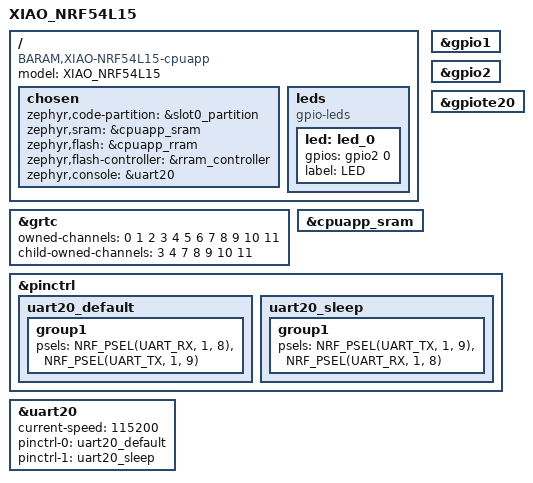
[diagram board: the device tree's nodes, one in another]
/dts-v1/;
#include <nordic/nrf54l15_cpuapp.dtsi>
#include "XIAO_NRF54L15-pinctrl.dtsi"

/ {
	model = "XIAO_NRF54L15";
	compatible = "BARAM,XIAO-NRF54L15-cpuapp";

	chosen {
		zephyr,code-partition = &slot0_partition;
		zephyr,sram = &cpuapp_sram;
		zephyr,flash = &cpuapp_rram;
		zephyr,flash-controller = &rram_controller;
    zephyr,console = &uart20;
	};

  leds {
    compatible = "gpio-leds";
    led: led_0 {
      gpios = <&gpio2 0 GPIO_ACTIVE_HIGH>;
      label = "LED";
    };  
  };
};

&grtc {
	owned-channels = <0 1 2 3 4 5 6 7 8 9 10 11>;
	/* Channels 7-11 reserved for Zero Latency IRQs, 3-4 for FLPR */
	child-owned-channels = <3 4 7 8 9 10 11>;
	status = "okay";
};

&cpuapp_sram {
	status = "okay";
};

#include <nordic/nrf54l15_partition.dtsi>

&gpio1 {
  status = "okay";
};

&gpio2 {
  status = "okay";
};

&gpiote20 {
  status = "okay";
};

&pinctrl {
  uart20_default: uart20_default {
    group1 {
      psels = <NRF_PSEL(UART_RX, 1, 8)>, <NRF_PSEL(UART_TX, 1, 9)>;
    };
  };

  uart20_sleep: uart20_sleep {
    group1 {
      psels = <NRF_PSEL(UART_TX, 1, 9)>,
				      <NRF_PSEL(UART_RX, 1, 8)>;
    };
  };
};

&uart20 {
  status = "okay";
  current-speed = <115200>;
  pinctrl-0 = <&uart20_default>;
  pinctrl-1 = <&uart20_sleep>;
  pinctrl-names = "default", "sleep";
};

